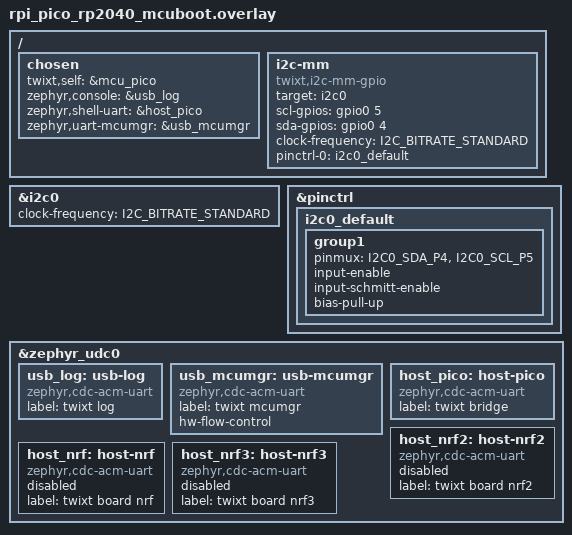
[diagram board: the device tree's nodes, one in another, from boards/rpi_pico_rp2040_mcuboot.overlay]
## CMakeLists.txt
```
# Copyright (c) 2026 Christoph Jans <jans.christoph@gmail.com>
# SPDX-License-Identifier: Apache-2.0

cmake_minimum_required(VERSION 3.20.0)

# One image per MCU: nrf2, nrf and nrf3 are boards with a shell, pico is the console bridge.
# MCU picks which MCU of boards/native_sim.overlay this image is.
set(MCU pico CACHE STRING "MCU to build: pico, the bridge, or the boards nrf2, nrf, nrf3")
if(MCU STREQUAL "pico")
  set(role bridge)
else()
  set(role board)
  list(APPEND EXTRA_CONF_FILE ${CMAKE_CURRENT_SOURCE_DIR}/board.conf)
endif()
list(APPEND EXTRA_DTC_OVERLAY_FILE ${CMAKE_CURRENT_SOURCE_DIR}/${role}.overlay)
list(APPEND DTS_EXTRA_CPPFLAGS -DTWIXT_SELF_LABEL=mcu_${MCU})

find_package(Zephyr REQUIRED HINTS $ENV{ZEPHYR_BASE})
project(twixt_shell)

target_sources(app PRIVATE src/${role}.c)
```

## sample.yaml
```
# Copyright (c) 2026 Christoph Jans <jans.christoph@gmail.com>
# SPDX-License-Identifier: Apache-2.0

sample:
  name: The shell of an MCU over twixt
common:
  build_only: true
  tags:
    - i2c
tests:
  sample.twixt.shell.native_sim.pico:
    platform_allow: native_sim
    integration_platforms:
      - native_sim
    extra_args: MCU=pico
  sample.twixt.shell.native_sim.nrf:
    platform_allow: native_sim
    integration_platforms:
      - native_sim
    extra_args: MCU=nrf
  sample.twixt.shell.nrf7002dk:
    platform_allow: nrf7002dk/nrf5340/cpuapp
    integration_platforms:
      - nrf7002dk/nrf5340/cpuapp
    extra_args: MCU=nrf
  sample.twixt.shell.rpi_pico:
    platform_allow: rpi_pico/rp2040/mcuboot
    integration_platforms:
      - rpi_pico/rp2040/mcuboot
    extra_configs:
      - CONFIG_BOOTLOADER_MCUBOOT=y
      - CONFIG_MCUBOOT_BOOTLOADER_MODE_SWAP_USING_OFFSET=y
      - CONFIG_MCUBOOT_SIGNATURE_KEY_FILE="bootloader/mcuboot/root-rsa-2048.pem"
```

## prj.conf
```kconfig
# Copyright (c) 2026 Christoph Jans <jans.christoph@gmail.com>
# SPDX-License-Identifier: Apache-2.0

CONFIG_I2C=y
CONFIG_SERIAL=y
CONFIG_LOG=y
CONFIG_LOG_BACKEND_SHOW_COLOR=n
```

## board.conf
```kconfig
# Copyright (c) 2026 Christoph Jans <jans.christoph@gmail.com>
# SPDX-License-Identifier: Apache-2.0

# Shell on the bus UART; the log stays on stdout, off the bus
CONFIG_SHELL=y
CONFIG_SHELL_LOG_BACKEND=n
CONFIG_SHELL_VT100_COLORS=n
```

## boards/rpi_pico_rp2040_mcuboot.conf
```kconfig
# Copyright (c) 2026 Christoph Jans <jans.christoph@gmail.com>
# SPDX-License-Identifier: Apache-2.0

# The bridge's ports to the laptop: USB CDC-ACM, set up in src/bridge.c
CONFIG_USB_DEVICE_STACK_NEXT=y
CONFIG_USBD_CDC_ACM_CLASS=y
CONFIG_CDC_ACM_SERIAL_INITIALIZE_AT_BOOT=n

# The bridge's own shell (twixt ping, ...) on its console port
CONFIG_SHELL=y
CONFIG_SHELL_VT100_COLORS=n
# The log goes to a CDC-ACM port: the class driver itself must not log
CONFIG_USBD_CDC_ACM_LOG_LEVEL_OFF=y


# A peer NACKs during its own transfers: a request and a response of 64 bytes at 100 kHz
CONFIG_TWIXT_LINK_NACK_RETRY_MS=20

# MCUmgr, to update the image over USB
CONFIG_MCUMGR=y
CONFIG_NET_BUF=y
CONFIG_ZCBOR=y
CONFIG_CRC=y
CONFIG_BASE64=y
CONFIG_FLASH=y
CONFIG_FLASH_MAP=y
CONFIG_STREAM_FLASH=y
CONFIG_IMG_MANAGER=y
CONFIG_IMG_ERASE_PROGRESSIVELY=y
CONFIG_MCUMGR_GRP_IMG=y
CONFIG_MCUMGR_GRP_OS=y
CONFIG_MCUMGR_GRP_OS_MCUMGR_PARAMS=y
CONFIG_REBOOT=y
CONFIG_SYSTEM_WORKQUEUE_STACK_SIZE=2048
CONFIG_UART_MCUMGR=y
CONFIG_MCUMGR_TRANSPORT_UART=y
```

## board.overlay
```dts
/*
 * Copyright (c) 2026 Christoph Jans <jans.christoph@gmail.com>
 *
 * SPDX-License-Identifier: Apache-2.0
 */

/* A board: shell on a UART to the bridge */

/ {
	chosen {
		zephyr,shell-uart = &bus_uart;
	};

	bus_uart: bus-uart {
		compatible = "twixt,uart";
		peer = <&mcu_pico>;
	};
};
```

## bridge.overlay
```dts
/*
 * Copyright (c) 2026 Christoph Jans <jans.christoph@gmail.com>
 *
 * SPDX-License-Identifier: Apache-2.0
 */

/* The console bridge: per board a UART over the bus, bridged to a serial port
 * to the laptop, host_<board>. The board's overlay (boards/) has the host ports,
 * disabled: a PTY on native_sim, USB CDC-ACM on the Raspberry Pi Pico.
 */

/ {
	bus_uart_nrf2: bus-uart-nrf2 {
		compatible = "twixt,uart";
		peer = <&mcu_nrf2>;
	};

	bridge-a {
		compatible = "zephyr,uart-bridge";
		peers = <&bus_uart_nrf2 &host_nrf2>;
	};

	bus_uart_nrf: bus-uart-nrf {
		compatible = "twixt,uart";
		peer = <&mcu_nrf>;
	};

	bridge-b {
		compatible = "zephyr,uart-bridge";
		peers = <&bus_uart_nrf &host_nrf>;
	};

	bus_uart_nrf3: bus-uart-nrf3 {
		compatible = "twixt,uart";
		peer = <&mcu_nrf3>;
	};

	bridge-c {
		compatible = "zephyr,uart-bridge";
		peers = <&bus_uart_nrf3 &host_nrf3>;
	};
};

&host_nrf2 {
	status = "okay";
};

&host_nrf {
	status = "okay";
};

&host_nrf3 {
	status = "okay";
};
```

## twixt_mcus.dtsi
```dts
/*
 * Copyright (c) 2026 Christoph Jans <jans.christoph@gmail.com>
 *
 * SPDX-License-Identifier: Apache-2.0
 */

/* The MCUs on the bus, the same for every image: included in the I2C bus node
 * of each board's overlay (boards/). The bridge has the highest address: when
 * it and a board start at the same moment, the board's request wins.
 */

mcu_nrf2: nrf2@10 {
	compatible = "twixt,mcu";
	reg = <0x10>;
};

mcu_nrf: nrf@11 {
	compatible = "twixt,mcu";
	reg = <0x11>;
};

mcu_nrf3: nrf3@12 {
	compatible = "twixt,mcu";
	reg = <0x12>;
};

mcu_pico: pico@70 {
	compatible = "twixt,mcu";
	reg = <0x70>;
};
```

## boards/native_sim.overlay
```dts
/*
 * Copyright (c) 2026 Christoph Jans <jans.christoph@gmail.com>
 *
 * SPDX-License-Identifier: Apache-2.0
 */

/ {
	chosen {
		twixt,self = &TWIXT_SELF_LABEL;
	};

	/* The bridge's ports to the laptop (bridge.overlay enables them):
	 * "pty-nrf2 connected to pseudotty: /dev/pts/N"
	 */
	host_nrf2: pty-nrf2 {
		compatible = "zephyr,native-pty-uart";
		current-speed = <0>;
		status = "disabled";
	};

	host_nrf: pty-nrf {
		compatible = "zephyr,native-pty-uart";
		current-speed = <0>;
		status = "disabled";
	};

	host_nrf3: pty-nrf3 {
		compatible = "zephyr,native-pty-uart";
		current-speed = <0>;
		status = "disabled";
	};
};

&i2c0 {
	compatible = "twixt,i2c-mm-native";
	bus-id = <1>;
	start-window-us = <2000>;

#include "../twixt_mcus.dtsi"
};
```

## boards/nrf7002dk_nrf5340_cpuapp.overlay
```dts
/*
 * Copyright (c) 2026 Christoph Jans <jans.christoph@gmail.com>
 *
 * SPDX-License-Identifier: Apache-2.0
 */

/* The bus on the Arduino SDA P1.02, SCL P1.03, at 1.8 V: TWIS2 is the target, the controller
 * software on the same pins (twixt,i2c-mm-gpio), as the TWIM cannot detect lost arbitration.
 */

#include <zephyr/dt-bindings/i2c/i2c.h>

/ {
	chosen {
		twixt,self = &TWIXT_SELF_LABEL;
	};

	i2c-mm {
		compatible = "twixt,i2c-mm-gpio";
		target = <&i2c2>;
		scl-gpios = <&gpio1 3 0>;
		sda-gpios = <&gpio1 2 0>;
		clock-frequency = <I2C_BITRATE_STANDARD>;
		#address-cells = <1>;
		#size-cells = <0>;

#include "../twixt_mcus.dtsi"
	};
};

&arduino_i2c {
	status = "disabled";
};

&i2c2 {
	compatible = "nordic,nrf-twis";
	status = "okay";
	pinctrl-0 = <&i2c2_twis_default>;
	pinctrl-1 = <&i2c2_twis_sleep>;
	pinctrl-names = "default", "sleep";
};

&pinctrl {
	i2c2_twis_default: i2c2_twis_default {
		group1 {
			psels = <NRF_PSEL(TWIS_SDA, 1, 2)>,
				<NRF_PSEL(TWIS_SCL, 1, 3)>;
		};
	};

	i2c2_twis_sleep: i2c2_twis_sleep {
		group1 {
			psels = <NRF_PSEL(TWIS_SDA, 1, 2)>,
				<NRF_PSEL(TWIS_SCL, 1, 3)>;
			low-power-enable;
		};
	};
};
```

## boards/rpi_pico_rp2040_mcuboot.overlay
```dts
/*
 * Copyright (c) 2026 Christoph Jans <jans.christoph@gmail.com>
 *
 * SPDX-License-Identifier: Apache-2.0
 */

/* The bridge. The bus on GP4 (pin 6), GP5 (pin 7), at 3.3 V: I2C0 is the target, the controller
 * software on the same pins (twixt,i2c-mm-gpio). pinctrl-0 gives the pins back to I2C0.
 */

#include <zephyr/dt-bindings/i2c/i2c.h>

/ {
	chosen {
		twixt,self = &mcu_pico;
		zephyr,console = &usb_log;
		zephyr,shell-uart = &host_pico;
		zephyr,uart-mcumgr = &usb_mcumgr;
	};

	i2c-mm {
		compatible = "twixt,i2c-mm-gpio";
		target = <&i2c0>;
		scl-gpios = <&gpio0 5 0>;
		sda-gpios = <&gpio0 4 0>;
		clock-frequency = <I2C_BITRATE_STANDARD>;
		pinctrl-0 = <&i2c0_default>;
		pinctrl-names = "default";
		#address-cells = <1>;
		#size-cells = <0>;

#include "../twixt_mcus.dtsi"
	};
};

&i2c0 {
	clock-frequency = <I2C_BITRATE_STANDARD>;
};

&pinctrl {
	i2c0_default: i2c0_default {
		group1 {
			pinmux = <I2C0_SDA_P4>, <I2C0_SCL_P5>;
			input-enable;
			input-schmitt-enable;
			bias-pull-up; /* weak; the bus needs its own pull-ups */
		};
	};
};

/* The bridge's ports to the laptop (bridge.overlay enables them) */
&zephyr_udc0 {
	/* The same order on every twixt Pico: if00 the log, if02 MCUmgr, if04 the bridge's shell,
	 * then the boards. Only MCUmgr waits for the host (hw-flow-control): it writes its answers
	 * with poll_out, which drops what does not fit otherwise.
	 */
	usb_log: usb-log {
		compatible = "zephyr,cdc-acm-uart";
		label = "twixt log";
	};

	usb_mcumgr: usb-mcumgr {
		compatible = "zephyr,cdc-acm-uart";
		label = "twixt mcumgr";
		hw-flow-control;
	};

	host_pico: host-pico {
		compatible = "zephyr,cdc-acm-uart";
		label = "twixt bridge";
		status = "okay";
	};

	host_nrf2: host-nrf2 {
		compatible = "zephyr,cdc-acm-uart";
		label = "twixt board nrf2";
		status = "disabled";
	};

	host_nrf: host-nrf {
		compatible = "zephyr,cdc-acm-uart";
		label = "twixt board nrf";
		status = "disabled";
	};

	host_nrf3: host-nrf3 {
		compatible = "zephyr,cdc-acm-uart";
		label = "twixt board nrf3";
		status = "disabled";
	};

};
```

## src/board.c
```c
/*
 * Copyright (c) 2026 Christoph Jans <jans.christoph@gmail.com>
 *
 * SPDX-License-Identifier: Apache-2.0
 *
 * A board on the bus: its shell is on a UART over the bus to the bridge
 * (board.overlay), with the "twixt" commands. Its prompt is its name.
 */

#include <stdio.h>
#include <zephyr/kernel.h>
#include <zephyr/logging/log.h>
#include <zephyr/shell/shell_uart.h>

#include <twixt/twixt.h>

LOG_MODULE_REGISTER(board, LOG_LEVEL_INF);

int main(void)
{
	static char prompt[32];

	snprintf(prompt, sizeof(prompt), "%s:~$ ", twixt_self_name());
	shell_prompt_change(shell_backend_uart_get_ptr(), prompt);

	LOG_INF("%s at 0x%02x, shell on the bus", twixt_self_name(), twixt_self_addr());
	return 0;
}
```

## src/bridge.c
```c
/*
 * Copyright (c) 2026 Christoph Jans <jans.christoph@gmail.com>
 *
 * SPDX-License-Identifier: Apache-2.0
 *
 * The console bridge: devicetree does the work (bridge.overlay). With USB
 * CDC-ACM ports to the laptop (Raspberry Pi Pico), it brings up the USB device
 * with all of them.
 */

#include <zephyr/kernel.h>
#include <zephyr/logging/log.h>

#include <twixt/twixt.h>

LOG_MODULE_REGISTER(bridge, LOG_LEVEL_INF);

#if DT_HAS_COMPAT_STATUS_OKAY(zephyr_cdc_acm_uart)

#include <zephyr/usb/usbd.h>

/* Zephyr's VID and a PID for testing; a product needs its own */
USBD_DEVICE_DEFINE(bridge_usbd, DEVICE_DT_GET(DT_NODELABEL(zephyr_udc0)), 0x2fe3, 0x0004);
USBD_DESC_LANG_DEFINE(bridge_lang);
USBD_DESC_MANUFACTURER_DEFINE(bridge_mfr, "twixt");
USBD_DESC_PRODUCT_DEFINE(bridge_product, "twixt pico");
USBD_DESC_CONFIG_DEFINE(bridge_cfg_desc, "FS Configuration");
USBD_CONFIGURATION_DEFINE(bridge_config, 0, 125, &bridge_cfg_desc);

static int usb_init(void)
{
	struct usbd_desc_node *const descs[] = {&bridge_lang, &bridge_mfr, &bridge_product};
	int err;

	for (size_t i = 0; i < ARRAY_SIZE(descs); i++) {
		err = usbd_add_descriptor(&bridge_usbd, descs[i]);
		if (err) {
			return err;
		}
	}
	err = usbd_add_configuration(&bridge_usbd, USBD_SPEED_FS, &bridge_config);
	if (err) {
		return err;
	}
	err = usbd_register_all_classes(&bridge_usbd, USBD_SPEED_FS, 1, NULL);
	if (err) {
		return err;
	}
	/* CDC-ACM has more than one interface per port: interface association */
	usbd_device_set_code_triple(&bridge_usbd, USBD_SPEED_FS, USB_BCC_MISCELLANEOUS, 0x02, 0x01);

	err = usbd_init(&bridge_usbd);
	if (err) {
		return err;
	}
	return usbd_enable(&bridge_usbd);
}

#endif

int main(void)
{
#if DT_HAS_COMPAT_STATUS_OKAY(zephyr_cdc_acm_uart)
	int err = usb_init();

	if (err) {
		LOG_ERR("USB: %d", err);
	}
#endif
	LOG_INF("%s at 0x%02x: console bridge", twixt_self_name(), twixt_self_addr());
	return 0;
}
```
